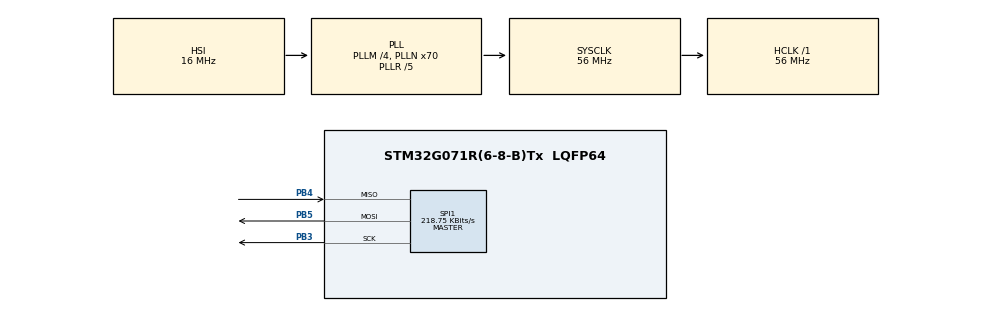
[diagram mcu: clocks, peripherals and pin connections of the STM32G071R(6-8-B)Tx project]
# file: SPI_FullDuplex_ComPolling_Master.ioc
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Mcu.Family=STM32G0
Mcu.Name=STM32G071R(6-8-B)Tx
Mcu.Package=LQFP64
PB3.GPIO_PuPd=GPIO_PULLDOWN
PB3.GPIO_Speed=GPIO_SPEED_FREQ_VERY_HIGH
PB3.Mode=Full_Duplex_Master
PB3.Signal=SPI1_SCK
PB4.GPIO_PuPd=GPIO_PULLDOWN
PB4.GPIO_Speed=GPIO_SPEED_FREQ_VERY_HIGH
PB4.Mode=Full_Duplex_Master
PB4.Signal=SPI1_MISO
PB5.GPIO_PuPd=GPIO_PULLDOWN
PB5.GPIO_Speed=GPIO_SPEED_FREQ_VERY_HIGH
PB5.Mode=Full_Duplex_Master
PB5.Signal=SPI1_MOSI
ProjectManager.HeapSize=0x200
ProjectManager.StackSize=0x400
ProjectManager.TargetToolchain=EWARM V8.50
RCC.ADCFreq_Value=56000000
RCC.AHBFreq_Value=56000000
RCC.CodegenConfigPeriph=false
RCC.CortexFreq_Value=56000000
RCC.EXTERNAL_CLOCK_VALUE=12288000
RCC.HCLKFreq_Value=56000000
RCC.HSE_VALUE=8000000
RCC.HSI_VALUE=16000000
RCC.LSE_VALUE=32768
RCC.PLLM=RCC_PLLM_DIV4
RCC.PLLN=70
RCC.PLLP=RCC_PLLP_DIV10
RCC.PLLQ=RCC_PLLQ_DIV5
RCC.PLLR=RCC_PLLR_DIV5
RCC.SYSCLKFreq_VALUE=56000000
RCC.SYSCLKSource=RCC_SYSCLKSOURCE_PLLCLK
RCC.VCOOutputFreq_Value=280000000
SPI1.BaudRatePrescaler=SPI_BAUDRATEPRESCALER_256
SPI1.CLKPhase=SPI_PHASE_1EDGE
SPI1.CLKPolarity=SPI_POLARITY_LOW
SPI1.CRCCalculation=SPI_CRCCALCULATION_DISABLE
SPI1.CalculateBaudRate=218.75 KBits/s
SPI1.DataSize=SPI_DATASIZE_16BIT
SPI1.Direction=SPI_DIRECTION_2LINES
SPI1.FirstBit=SPI_FIRSTBIT_MSB
SPI1.GPIO_SPEED=GPIO_SPEED_FREQ_HIGH
SPI1.Mode=SPI_MODE_MASTER
SPI1.NSS=SPI_NSS_SOFT
SPI1.NSSPMode=SPI_NSS_PULSE_ENABLE
SPI1.TIMode=SPI_TIMODE_DISABLE
SPI1.VirtualType=VM_MASTER
VP_SYS_VS_DBSignals.Mode=DisableDeadBatterySignals
board=custom

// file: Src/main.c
/* USER CODE BEGIN Header */
/**
  ******************************************************************************
  * @file    SPI/SPI_FullDuplex_ComPolling_Master/Src/main.c
  * @author  MCD Application Team
  * @brief   This sample code shows how to use STM32G0xx SPI HAL API to transmit
  *          and receive a data buffer with a communication process based on
  *          Polling transfer.
  *          The communication is done using 2 Boards.
  ******************************************************************************
  * @attention
  *
  * Copyright (c) 2018-2020 STMicroelectronics.
  * All rights reserved.
  *
  * This software is licensed under terms that can be found in the LICENSE file
  * in the root directory of this software component.
  * If no LICENSE file comes with this software, it is provided AS-IS.
  *
  ******************************************************************************
  */
/* USER CODE END Header */
#include "main.h"

SPI_HandleTypeDef hspi1;

/* USER CODE BEGIN PV */
/* Buffer used for transmission */
uint16_t aTxBuffer[] = {0x1234,0x5678,0x9ABC,0xDEF0,0x1234,0x5678,0x9ABC,0xDEF0,0x1234,0x5678,0x9ABC,0xDEF0,0x1234,0x5678,0x9ABC,0xDEF0,0x1234,0x5678,0x9ABC,0xDEF0,0x1234,0x5678,0x9ABC,0xDEF0,0x1234,0x5678,0x9ABC,0xDEF0,0x1234,0x5678,0x9ABC,0xDEF0,0x1234,0x5678,0x9ABC,0xDEF0,0x1234,0x5678,0x9ABC,0xDEF0};
__IO uint16_t ubNbDataToTransmit = BUFFERSIZE;
__IO uint8_t ubTransmitIndex = 0;

/* Buffer used for reception */
uint16_t aRxBuffer[BUFFERSIZE];
__IO uint16_t ubNbDataToReceive = BUFFERSIZE;
__IO uint8_t ubReceiveIndex = 0;
/* USER CODE END PV */

void SystemClock_Config(void);
static void MX_GPIO_Init(void);
static void MX_SPI1_Init(void);
/* USER CODE BEGIN PFP */
static uint16_t Buffercmp(uint8_t *pBuffer1, uint8_t *pBuffer2, uint16_t BufferLength);

/* USER CODE END PFP */

int main(void)
{
  /* USER CODE BEGIN 1 */

  /* STM32G0xx HAL library initialization:
       - Configure the Flash prefetch
       - Systick timer is configured by default as source of time base, but user
         can eventually implement his proper time base source (a general purpose
         timer for example or other time source), keeping in mind that Time base
         duration should be kept 1ms since PPP_TIMEOUT_VALUEs are defined and
         handled in milliseconds basis.
       - Low Level Initialization
     */
  /* USER CODE END 1 */

  /* MCU Configuration--------------------------------------------------------*/

  /* Reset of all peripherals, Initializes the Flash interface and the Systick. */
  HAL_Init();

  /* Configure the system clock */
  SystemClock_Config();

  /* Initialize all configured peripherals */
  MX_GPIO_Init();
  MX_SPI1_Init();
  /* USER CODE BEGIN 2 */

  /* Configure LED4 */
  BSP_LED_Init(LED4);

  /* Configure User push-button button */
  BSP_PB_Init(BUTTON_USER, BUTTON_MODE_GPIO);

  /* Wait for User push-button press before starting the Communication */
  while (BSP_PB_GetState(BUTTON_USER) != GPIO_PIN_RESET)
  {
    BSP_LED_Toggle(LED4);
    HAL_Delay(100);
  }
  BSP_LED_Off(LED4);

  /*##-1- Start the Full Duplex Communication process ########################*/
  /* Enable SPI before start transmission */
  LL_SPI_Enable(hspi1.Instance);

  while(ubNbDataToReceive > 0)
  {
    /* Check TXE flag to transmit data */
    if(( LL_SPI_IsActiveFlag_TXE(hspi1.Instance)) && (ubNbDataToTransmit > 0))
    {
      /* Transmit 16bit Data */
      LL_SPI_TransmitData16(hspi1.Instance, aTxBuffer[ubTransmitIndex++]);
      ubNbDataToTransmit--;
    }
    /* Check RXE flag */
    if(LL_SPI_IsActiveFlag_RXNE(hspi1.Instance))
    {
      /* Receive 16bit Data */
      aRxBuffer[ubReceiveIndex++] = LL_SPI_ReceiveData16(hspi1.Instance);
      ubNbDataToReceive--;
    }
  }

  /*##-3- Compare the sent and received buffers ##############################*/
  /* Compare the sent and received buffers */
  if (Buffercmp((uint8_t *)aTxBuffer, (uint8_t *)aRxBuffer, COUNTOF(aTxBuffer)))
  {
    /* Transfer error in transmission process */
    Error_Handler();
  }
  else
  {
    /* Turn LED4 on: Transfer in transmission/Reception process is correct */
    BSP_LED_On(LED4);
  }
  /* USER CODE END 2 */

  /* Infinite loop */
  while (1)
  {

  }
}

void SystemClock_Config(void)
{
  RCC_OscInitTypeDef RCC_OscInitStruct = {0};
  RCC_ClkInitTypeDef RCC_ClkInitStruct = {0};

  /** Configure the main internal regulator output voltage
  */
  HAL_PWREx_ControlVoltageScaling(PWR_REGULATOR_VOLTAGE_SCALE1);

  /** Initializes the RCC Oscillators according to the specified parameters
  * in the RCC_OscInitTypeDef structure.
  */
  RCC_OscInitStruct.OscillatorType = RCC_OSCILLATORTYPE_HSI;
  RCC_OscInitStruct.HSIState = RCC_HSI_ON;
  RCC_OscInitStruct.HSIDiv = RCC_HSI_DIV1;
  RCC_OscInitStruct.HSICalibrationValue = RCC_HSICALIBRATION_DEFAULT;
  RCC_OscInitStruct.PLL.PLLState = RCC_PLL_ON;
  RCC_OscInitStruct.PLL.PLLSource = RCC_PLLSOURCE_HSI;
  RCC_OscInitStruct.PLL.PLLM = RCC_PLLM_DIV4;
  RCC_OscInitStruct.PLL.PLLN = 70;
  RCC_OscInitStruct.PLL.PLLP = RCC_PLLP_DIV10;
  RCC_OscInitStruct.PLL.PLLQ = RCC_PLLQ_DIV5;
  RCC_OscInitStruct.PLL.PLLR = RCC_PLLR_DIV5;
  if (HAL_RCC_OscConfig(&RCC_OscInitStruct) != HAL_OK)
  {
    Error_Handler();
  }

  /** Initializes the CPU, AHB and APB buses clocks
  */
  RCC_ClkInitStruct.ClockType = RCC_CLOCKTYPE_HCLK|RCC_CLOCKTYPE_SYSCLK
                              |RCC_CLOCKTYPE_PCLK1;
  RCC_ClkInitStruct.SYSCLKSource = RCC_SYSCLKSOURCE_PLLCLK;
  RCC_ClkInitStruct.AHBCLKDivider = RCC_SYSCLK_DIV1;
  RCC_ClkInitStruct.APB1CLKDivider = RCC_HCLK_DIV1;

  if (HAL_RCC_ClockConfig(&RCC_ClkInitStruct, FLASH_LATENCY_2) != HAL_OK)
  {
    Error_Handler();
  }
}

static void MX_SPI1_Init(void)
{

  /* SPI1 parameter configuration*/
  hspi1.Instance = SPI1;
  hspi1.Init.Mode = SPI_MODE_MASTER;
  hspi1.Init.Direction = SPI_DIRECTION_2LINES;
  hspi1.Init.DataSize = SPI_DATASIZE_16BIT;
  hspi1.Init.CLKPolarity = SPI_POLARITY_LOW;
  hspi1.Init.CLKPhase = SPI_PHASE_1EDGE;
  hspi1.Init.NSS = SPI_NSS_SOFT;
  hspi1.Init.BaudRatePrescaler = SPI_BAUDRATEPRESCALER_256;
  hspi1.Init.FirstBit = SPI_FIRSTBIT_MSB;
  hspi1.Init.TIMode = SPI_TIMODE_DISABLE;
  hspi1.Init.CRCCalculation = SPI_CRCCALCULATION_DISABLE;
  hspi1.Init.CRCPolynomial = 7;
  hspi1.Init.CRCLength = SPI_CRC_LENGTH_DATASIZE;
  hspi1.Init.NSSPMode = SPI_NSS_PULSE_ENABLE;
  if (HAL_SPI_Init(&hspi1) != HAL_OK)
  {
    Error_Handler();
  }

}

static void MX_GPIO_Init(void)
{

  /* GPIO Ports Clock Enable */
  __HAL_RCC_GPIOB_CLK_ENABLE();

}

/* USER CODE BEGIN 4 */

/**
  * @brief  Compares two buffers.
  * @param  pBuffer1, pBuffer2: buffers to be compared.
  * @param  BufferLength: buffer's length
  * @retval 0  : pBuffer1 identical to pBuffer2
  *         >0 : pBuffer1 differs from pBuffer2
  */
static uint16_t Buffercmp(uint8_t* pBuffer1, uint8_t* pBuffer2, uint16_t BufferLength)
{
  while (BufferLength--)
  {
    if((*pBuffer1) != *pBuffer2)
    {
      return BufferLength;
    }
    pBuffer1++;
    pBuffer2++;
  }

  return 0;
}

/* USER CODE END 4 */

void Error_Handler(void)
{
  /* USER CODE BEGIN Error_Handler_Debug */
  /* User can add his own implementation to report the HAL error return state */
  while(1)
  {
    /* Toggle LED4 for error */
    BSP_LED_Toggle(LED4);
    HAL_Delay(1000);
  }
  /* USER CODE END Error_Handler_Debug */
}
